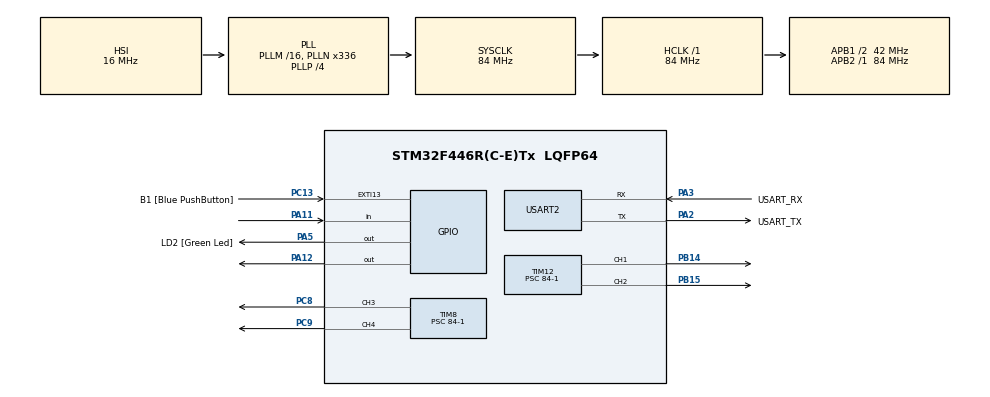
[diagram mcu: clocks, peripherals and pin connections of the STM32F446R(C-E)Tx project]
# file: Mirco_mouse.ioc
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Mcu.Family=STM32F4
Mcu.Name=STM32F446R(C-E)Tx
Mcu.Package=LQFP64
NVIC.PriorityGroup=NVIC_PRIORITYGROUP_0
NVIC.TIM1_BRK_TIM9_IRQn=true\:0\:0\:false\:false\:true\:true\:true\:true
NVIC.TIM1_CC_IRQn=true\:0\:0\:false\:false\:true\:true\:true\:true
NVIC.TIM1_TRG_COM_TIM11_IRQn=true\:0\:0\:false\:false\:true\:true\:true\:true
NVIC.TIM1_UP_TIM10_IRQn=true\:0\:0\:false\:false\:true\:true\:true\:true
NVIC.TIM8_BRK_TIM12_IRQn=true\:0\:0\:false\:false\:true\:true\:true\:true
PA11.Signal=GPIO_Input
PA12.Signal=GPIO_Output
PA13.GPIO_Label=TMS
PA13.Mode=Serial_Wire
PA13.Signal=SYS_JTMS-SWDIO
PA14.GPIO_Label=TCK
PA14.Mode=Serial_Wire
PA14.Signal=SYS_JTCK-SWCLK
PA2.GPIO_Label=USART_TX
PA2.Mode=Asynchronous
PA2.Signal=USART2_TX
PA3.GPIO_Label=USART_RX
PA3.Mode=Asynchronous
PA3.Signal=USART2_RX
PA5.GPIO_Label=LD2 [Green Led]
PA5.Signal=GPIO_Output
PB14.Signal=S_TIM12_CH1
PB15.Signal=S_TIM12_CH2
PB3.GPIO_Label=SWO
PB3.Signal=SYS_JTDO-SWO
PC13.GPIO_Label=B1 [Blue PushButton]
PC13.GPIO_ModeDefaultEXTI=GPIO_MODE_IT_FALLING
PC13.Signal=GPXTI13
PC14-OSC32_IN.Mode=LSE-External-Oscillator
PC14-OSC32_IN.Signal=RCC_OSC32_IN
PC15-OSC32_OUT.Mode=LSE-External-Oscillator
PC15-OSC32_OUT.Signal=RCC_OSC32_OUT
PC8.Signal=S_TIM8_CH3
PC9.Signal=S_TIM8_CH4
PH0-OSC_IN.Mode=HSE-External-Oscillator
PH0-OSC_IN.Signal=RCC_OSC_IN
PH1-OSC_OUT.Mode=HSE-External-Oscillator
PH1-OSC_OUT.Signal=RCC_OSC_OUT
ProjectManager.HeapSize=0x200
ProjectManager.StackSize=0x400
ProjectManager.TargetToolchain=STM32CubeIDE
RCC.48MHZClocksFreq_Value=84000000
RCC.AHBFreq_Value=84000000
RCC.APB1CLKDivider=RCC_HCLK_DIV2
RCC.APB1Freq_Value=42000000
RCC.APB1TimFreq_Value=84000000
RCC.APB2Freq_Value=84000000
RCC.APB2TimFreq_Value=84000000
RCC.CortexFreq_Value=84000000
RCC.FLatency-AdvancedSettings=FLASH_LATENCY_2
RCC.HCLKFreq_Value=84000000
RCC.HSE_VALUE=8000000
RCC.HSI_VALUE=16000000
RCC.PLLN=336
RCC.PLLP=RCC_PLLP_DIV4
RCC.SYSCLKFreq_VALUE=84000000
RCC.SYSCLKSource=RCC_SYSCLKSOURCE_PLLCLK
RCC.USBFreq_Value=168000000
RCC.VCOOutputFreq_Value=336000000
SH.S_TIM12_CH1.0=TIM12_CH1,PWM Generation1 CH1
SH.S_TIM12_CH2.0=TIM12_CH2,PWM Generation2 CH2
SH.S_TIM8_CH3.0=TIM8_CH3,PWM Generation3 CH3
SH.S_TIM8_CH4.0=TIM8_CH4,PWM Generation4 CH4
TIM1.Channel-Output\ Compare4\ No\ Output=TIM_CHANNEL_4
TIM1.Period=2000
TIM1.Prescaler=84-1
TIM12.Channel-PWM\ Generation1\ CH1=TIM_CHANNEL_1
TIM12.Channel-PWM\ Generation2\ CH2=TIM_CHANNEL_2
TIM12.Period=4200-1
TIM12.Prescaler=84-1
TIM8.Channel-PWM\ Generation3\ CH3=TIM_CHANNEL_3
TIM8.Channel-PWM\ Generation4\ CH4=TIM_CHANNEL_4
TIM8.Period=4200-1
TIM8.Prescaler=84-1
USART2.VirtualMode=VM_ASYNC
VP_TIM12_VS_ClockSourceINT.Mode=Internal
VP_TIM1_VS_ClockSourceINT.Mode=Internal
VP_TIM1_VS_no_output4.Mode=Output Compare4 No Output
VP_TIM8_VS_ClockSourceINT.Mode=Internal
board=NUCLEO-F446RE

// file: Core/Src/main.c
/* USER CODE BEGIN Header */
/**
  ******************************************************************************
  * @file           : main.c
  * @brief          : Main program body
  ******************************************************************************
  * @attention
  *
  * Copyright (c) 2026 STMicroelectronics.
  * All rights reserved.
  *
  * This software is licensed under terms that can be found in the LICENSE file
  * in the root directory of this software component.
  * If no LICENSE file comes with this software, it is provided AS-IS.
  *
  ******************************************************************************
  */
/* USER CODE END Header */
#include "main.h"

TIM_HandleTypeDef htim1;
TIM_HandleTypeDef htim8;
TIM_HandleTypeDef htim12;

UART_HandleTypeDef huart2;

/* USER CODE BEGIN PV */
uint16_t pwm_duty_motorF = 0;
uint16_t pwm_duty_motorR = 0;
/* USER CODE END PV */

void SystemClock_Config(void);
static void MX_GPIO_Init(void);
static void MX_USART2_UART_Init(void);
static void MX_TIM8_Init(void);
static void MX_TIM1_Init(void);
static void MX_TIM12_Init(void);

int main(void)
{

  /* MCU Configuration--------------------------------------------------------*/

  /* Reset of all peripherals, Initializes the Flash interface and the Systick. */
  HAL_Init();

  /* Configure the system clock */
  SystemClock_Config();

  /* Initialize all configured peripherals */
  MX_GPIO_Init();
  MX_USART2_UART_Init();
  MX_TIM8_Init();
  MX_TIM1_Init();
  MX_TIM12_Init();
  /* USER CODE BEGIN 2 */
  HAL_TIM_PWM_Start(&htim8, TIM_CHANNEL_4);
  HAL_TIM_PWM_Start(&htim8, TIM_CHANNEL_3);
  HAL_TIM_PWM_Start(&htim12, TIM_CHANNEL_2);
  HAL_TIM_PWM_Start(&htim12, TIM_CHANNEL_1);

  HAL_TIM_Base_Start_IT(&htim1);
  /* USER CODE END 2 */

  /* Infinite loop */
  while (1)
  {

  }
}

void SystemClock_Config(void)
{
  RCC_OscInitTypeDef RCC_OscInitStruct = {0};
  RCC_ClkInitTypeDef RCC_ClkInitStruct = {0};

  /** Configure the main internal regulator output voltage
  */
  __HAL_RCC_PWR_CLK_ENABLE();
  __HAL_PWR_VOLTAGESCALING_CONFIG(PWR_REGULATOR_VOLTAGE_SCALE3);

  /** Initializes the RCC Oscillators according to the specified parameters
  * in the RCC_OscInitTypeDef structure.
  */
  RCC_OscInitStruct.OscillatorType = RCC_OSCILLATORTYPE_HSI;
  RCC_OscInitStruct.HSIState = RCC_HSI_ON;
  RCC_OscInitStruct.HSICalibrationValue = RCC_HSICALIBRATION_DEFAULT;
  RCC_OscInitStruct.PLL.PLLState = RCC_PLL_ON;
  RCC_OscInitStruct.PLL.PLLSource = RCC_PLLSOURCE_HSI;
  RCC_OscInitStruct.PLL.PLLM = 16;
  RCC_OscInitStruct.PLL.PLLN = 336;
  RCC_OscInitStruct.PLL.PLLP = RCC_PLLP_DIV4;
  RCC_OscInitStruct.PLL.PLLQ = 2;
  RCC_OscInitStruct.PLL.PLLR = 2;
  if (HAL_RCC_OscConfig(&RCC_OscInitStruct) != HAL_OK)
  {
    Error_Handler();
  }

  /** Initializes the CPU, AHB and APB buses clocks
  */
  RCC_ClkInitStruct.ClockType = RCC_CLOCKTYPE_HCLK|RCC_CLOCKTYPE_SYSCLK
                              |RCC_CLOCKTYPE_PCLK1|RCC_CLOCKTYPE_PCLK2;
  RCC_ClkInitStruct.SYSCLKSource = RCC_SYSCLKSOURCE_PLLCLK;
  RCC_ClkInitStruct.AHBCLKDivider = RCC_SYSCLK_DIV1;
  RCC_ClkInitStruct.APB1CLKDivider = RCC_HCLK_DIV2;
  RCC_ClkInitStruct.APB2CLKDivider = RCC_HCLK_DIV1;

  if (HAL_RCC_ClockConfig(&RCC_ClkInitStruct, FLASH_LATENCY_2) != HAL_OK)
  {
    Error_Handler();
  }
}

static void MX_TIM1_Init(void)
{

  TIM_ClockConfigTypeDef sClockSourceConfig = {0};
  TIM_MasterConfigTypeDef sMasterConfig = {0};
  TIM_OC_InitTypeDef sConfigOC = {0};
  TIM_BreakDeadTimeConfigTypeDef sBreakDeadTimeConfig = {0};

  htim1.Instance = TIM1;
  htim1.Init.Prescaler = 84-1;
  htim1.Init.CounterMode = TIM_COUNTERMODE_UP;
  htim1.Init.Period = 2000;
  htim1.Init.ClockDivision = TIM_CLOCKDIVISION_DIV1;
  htim1.Init.RepetitionCounter = 0;
  htim1.Init.AutoReloadPreload = TIM_AUTORELOAD_PRELOAD_DISABLE;
  if (HAL_TIM_Base_Init(&htim1) != HAL_OK)
  {
    Error_Handler();
  }
  sClockSourceConfig.ClockSource = TIM_CLOCKSOURCE_INTERNAL;
  if (HAL_TIM_ConfigClockSource(&htim1, &sClockSourceConfig) != HAL_OK)
  {
    Error_Handler();
  }
  if (HAL_TIM_OC_Init(&htim1) != HAL_OK)
  {
    Error_Handler();
  }
  sMasterConfig.MasterOutputTrigger = TIM_TRGO_RESET;
  sMasterConfig.MasterSlaveMode = TIM_MASTERSLAVEMODE_DISABLE;
  if (HAL_TIMEx_MasterConfigSynchronization(&htim1, &sMasterConfig) != HAL_OK)
  {
    Error_Handler();
  }
  sConfigOC.OCMode = TIM_OCMODE_TIMING;
  sConfigOC.Pulse = 0;
  sConfigOC.OCPolarity = TIM_OCPOLARITY_HIGH;
  sConfigOC.OCFastMode = TIM_OCFAST_DISABLE;
  sConfigOC.OCIdleState = TIM_OCIDLESTATE_RESET;
  sConfigOC.OCNIdleState = TIM_OCNIDLESTATE_RESET;
  if (HAL_TIM_OC_ConfigChannel(&htim1, &sConfigOC, TIM_CHANNEL_4) != HAL_OK)
  {
    Error_Handler();
  }
  sBreakDeadTimeConfig.OffStateRunMode = TIM_OSSR_DISABLE;
  sBreakDeadTimeConfig.OffStateIDLEMode = TIM_OSSI_DISABLE;
  sBreakDeadTimeConfig.LockLevel = TIM_LOCKLEVEL_OFF;
  sBreakDeadTimeConfig.DeadTime = 0;
  sBreakDeadTimeConfig.BreakState = TIM_BREAK_DISABLE;
  sBreakDeadTimeConfig.BreakPolarity = TIM_BREAKPOLARITY_HIGH;
  sBreakDeadTimeConfig.AutomaticOutput = TIM_AUTOMATICOUTPUT_DISABLE;
  if (HAL_TIMEx_ConfigBreakDeadTime(&htim1, &sBreakDeadTimeConfig) != HAL_OK)
  {
    Error_Handler();
  }

}

static void MX_TIM8_Init(void)
{

  TIM_ClockConfigTypeDef sClockSourceConfig = {0};
  TIM_MasterConfigTypeDef sMasterConfig = {0};
  TIM_OC_InitTypeDef sConfigOC = {0};
  TIM_BreakDeadTimeConfigTypeDef sBreakDeadTimeConfig = {0};

  htim8.Instance = TIM8;
  htim8.Init.Prescaler = 84-1;
  htim8.Init.CounterMode = TIM_COUNTERMODE_UP;
  htim8.Init.Period = 4200-1;
  htim8.Init.ClockDivision = TIM_CLOCKDIVISION_DIV1;
  htim8.Init.RepetitionCounter = 0;
  htim8.Init.AutoReloadPreload = TIM_AUTORELOAD_PRELOAD_DISABLE;
  if (HAL_TIM_Base_Init(&htim8) != HAL_OK)
  {
    Error_Handler();
  }
  sClockSourceConfig.ClockSource = TIM_CLOCKSOURCE_INTERNAL;
  if (HAL_TIM_ConfigClockSource(&htim8, &sClockSourceConfig) != HAL_OK)
  {
    Error_Handler();
  }
  if (HAL_TIM_PWM_Init(&htim8) != HAL_OK)
  {
    Error_Handler();
  }
  sMasterConfig.MasterOutputTrigger = TIM_TRGO_RESET;
  sMasterConfig.MasterSlaveMode = TIM_MASTERSLAVEMODE_DISABLE;
  if (HAL_TIMEx_MasterConfigSynchronization(&htim8, &sMasterConfig) != HAL_OK)
  {
    Error_Handler();
  }
  sConfigOC.OCMode = TIM_OCMODE_PWM1;
  sConfigOC.Pulse = 0;
  sConfigOC.OCPolarity = TIM_OCPOLARITY_HIGH;
  sConfigOC.OCNPolarity = TIM_OCNPOLARITY_HIGH;
  sConfigOC.OCFastMode = TIM_OCFAST_DISABLE;
  sConfigOC.OCIdleState = TIM_OCIDLESTATE_RESET;
  sConfigOC.OCNIdleState = TIM_OCNIDLESTATE_RESET;
  if (HAL_TIM_PWM_ConfigChannel(&htim8, &sConfigOC, TIM_CHANNEL_3) != HAL_OK)
  {
    Error_Handler();
  }
  if (HAL_TIM_PWM_ConfigChannel(&htim8, &sConfigOC, TIM_CHANNEL_4) != HAL_OK)
  {
    Error_Handler();
  }
  sBreakDeadTimeConfig.OffStateRunMode = TIM_OSSR_DISABLE;
  sBreakDeadTimeConfig.OffStateIDLEMode = TIM_OSSI_DISABLE;
  sBreakDeadTimeConfig.LockLevel = TIM_LOCKLEVEL_OFF;
  sBreakDeadTimeConfig.DeadTime = 0;
  sBreakDeadTimeConfig.BreakState = TIM_BREAK_DISABLE;
  sBreakDeadTimeConfig.BreakPolarity = TIM_BREAKPOLARITY_HIGH;
  sBreakDeadTimeConfig.AutomaticOutput = TIM_AUTOMATICOUTPUT_DISABLE;
  if (HAL_TIMEx_ConfigBreakDeadTime(&htim8, &sBreakDeadTimeConfig) != HAL_OK)
  {
    Error_Handler();
  }
  HAL_TIM_MspPostInit(&htim8);

}

static void MX_TIM12_Init(void)
{

  TIM_ClockConfigTypeDef sClockSourceConfig = {0};
  TIM_OC_InitTypeDef sConfigOC = {0};

  htim12.Instance = TIM12;
  htim12.Init.Prescaler = 84-1;
  htim12.Init.CounterMode = TIM_COUNTERMODE_UP;
  htim12.Init.Period = 4200-1;
  htim12.Init.ClockDivision = TIM_CLOCKDIVISION_DIV1;
  htim12.Init.AutoReloadPreload = TIM_AUTORELOAD_PRELOAD_DISABLE;
  if (HAL_TIM_Base_Init(&htim12) != HAL_OK)
  {
    Error_Handler();
  }
  sClockSourceConfig.ClockSource = TIM_CLOCKSOURCE_INTERNAL;
  if (HAL_TIM_ConfigClockSource(&htim12, &sClockSourceConfig) != HAL_OK)
  {
    Error_Handler();
  }
  if (HAL_TIM_PWM_Init(&htim12) != HAL_OK)
  {
    Error_Handler();
  }
  sConfigOC.OCMode = TIM_OCMODE_PWM1;
  sConfigOC.Pulse = 0;
  sConfigOC.OCPolarity = TIM_OCPOLARITY_HIGH;
  sConfigOC.OCFastMode = TIM_OCFAST_DISABLE;
  if (HAL_TIM_PWM_ConfigChannel(&htim12, &sConfigOC, TIM_CHANNEL_1) != HAL_OK)
  {
    Error_Handler();
  }
  if (HAL_TIM_PWM_ConfigChannel(&htim12, &sConfigOC, TIM_CHANNEL_2) != HAL_OK)
  {
    Error_Handler();
  }
  HAL_TIM_MspPostInit(&htim12);

}

static void MX_USART2_UART_Init(void)
{

  huart2.Instance = USART2;
  huart2.Init.BaudRate = 115200;
  huart2.Init.WordLength = UART_WORDLENGTH_8B;
  huart2.Init.StopBits = UART_STOPBITS_1;
  huart2.Init.Parity = UART_PARITY_NONE;
  huart2.Init.Mode = UART_MODE_TX_RX;
  huart2.Init.HwFlowCtl = UART_HWCONTROL_NONE;
  huart2.Init.OverSampling = UART_OVERSAMPLING_16;
  if (HAL_UART_Init(&huart2) != HAL_OK)
  {
    Error_Handler();
  }

}

static void MX_GPIO_Init(void)
{
  GPIO_InitTypeDef GPIO_InitStruct = {0};

  /* GPIO Ports Clock Enable */
  __HAL_RCC_GPIOC_CLK_ENABLE();
  __HAL_RCC_GPIOH_CLK_ENABLE();
  __HAL_RCC_GPIOA_CLK_ENABLE();
  __HAL_RCC_GPIOB_CLK_ENABLE();

  /*Configure GPIO pin Output Level */
  HAL_GPIO_WritePin(GPIOA, LD2_Pin|GPIO_PIN_12, GPIO_PIN_RESET);

  /*Configure GPIO pin : B1_Pin */
  GPIO_InitStruct.Pin = B1_Pin;
  GPIO_InitStruct.Mode = GPIO_MODE_IT_FALLING;
  GPIO_InitStruct.Pull = GPIO_NOPULL;
  HAL_GPIO_Init(B1_GPIO_Port, &GPIO_InitStruct);

  /*Configure GPIO pins : LD2_Pin PA12 */
  GPIO_InitStruct.Pin = LD2_Pin|GPIO_PIN_12;
  GPIO_InitStruct.Mode = GPIO_MODE_OUTPUT_PP;
  GPIO_InitStruct.Pull = GPIO_NOPULL;
  GPIO_InitStruct.Speed = GPIO_SPEED_FREQ_LOW;
  HAL_GPIO_Init(GPIOA, &GPIO_InitStruct);

  /*Configure GPIO pin : PA11 */
  GPIO_InitStruct.Pin = GPIO_PIN_11;
  GPIO_InitStruct.Mode = GPIO_MODE_INPUT;
  GPIO_InitStruct.Pull = GPIO_NOPULL;
  HAL_GPIO_Init(GPIOA, &GPIO_InitStruct);

}

/* USER CODE BEGIN 4 */

void HAL_TIM_PeriodElapsedCallback(TIM_HandleTypeDef *htim){

    if(htim == &htim1){
    	TIM8->CCR3 = 500;
    	TIM8->CCR4 = 0;
    	TIM12->CCR1 = 500;
    	TIM12->CCR2 = 0;

    }

}

/* USER CODE END 4 */

void Error_Handler(void)
{
  __disable_irq();
  while (1)
  {
  }
}
